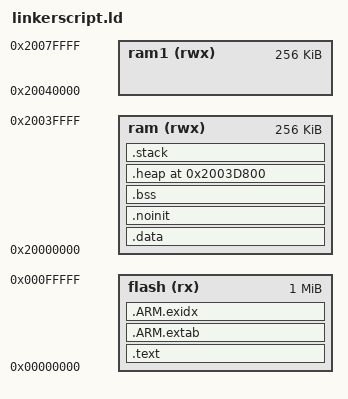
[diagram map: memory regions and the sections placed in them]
/* The MIT License (MIT)
 *
 * Copyright (c) 2021 Mathias Spiessens
 *
 * Permission is hereby granted, free of charge, to any person obtaining a copy
 * of this software, hardware and associated documentation files (the "Solution"), to deal
 * in the Solution without restriction, including without limitation the rights
 * to use, copy, modify, merge, publish, distribute, sublicense, and/or sell
 * copies of the Solution, and to permit persons to whom the Solution is
 * furnished to do so, subject to the following conditions:
 *
 * The above copyright notice and this permission notice shall be included in all
 * copies or substantial portions of the Solution.
 *
 * THE SOLUTION IS PROVIDED "AS IS", WITHOUT WARRANTY OF ANY KIND, EXPRESS OR
 * IMPLIED, INCLUDING BUT NOT LIMITED TO THE WARRANTIES OF MERCHANTABILITY,
 * FITNESS FOR A PARTICULAR PURPOSE AND NONINFRINGEMENT. IN NO EVENT SHALL THE
 * AUTHORS OR COPYRIGHT HOLDERS BE LIABLE FOR ANY CLAIM, DAMAGES OR OTHER
 * LIABILITY, WHETHER IN AN ACTION OF CONTRACT, TORT OR OTHERWISE, ARISING FROM,
 * OUT OF OR IN CONNECTION WITH THE SOLUTION OR THE USE OR OTHER DEALINGS IN THE
 * SOLUTION.
 */

OUTPUT_FORMAT ("elf32-littlearm", "elf32-bigarm", "elf32-littlearm")
SEARCH_DIR(.)
ENTRY(reset)

MEMORY
{
    flash (rx) : ORIGIN = 0x00000000, LENGTH = 1M 
    ram (rwx) : ORIGIN = 0x20000000, LENGTH = 256k
    ram1 (rwx) : ORIGIN = 0x20000000 + 256k, LENGTH = 256k
}

_heap_size = 8k;
_stack_size = 2k;

SECTIONS
{
    .text :
    {
        . = ALIGN(4);
        __Vectors = . ;
        KEEP(*(.vectors))

        . = ALIGN(4);
        *(.text*)

        KEEP(*(.init))
        KEEP(*(.fini))

        /* .ctors */
        *crtbegin.o(.ctors)
        *crtbegin?.o(.ctors)
        *(EXCLUDE_FILE(*crtend?.o *crtend.o) .ctors)
        *(SORT(.ctors.*))
        *(.ctors)

        /* .dtors */
        *crtbegin.o(.dtors)
        *crtbegin?.o(.dtors)
        *(EXCLUDE_FILE(*crtend?.o *crtend.o) .dtors)
        *(SORT(.dtors.*))
        *(.dtors)

        /* Read-only code (constants). */
        *(.rodata .rodata.* .constdata .constdata.* .conststring .conststring.*)

        KEEP(*(.eh_frame*))
    } > flash

    .ARM.extab :
    {
        *(.ARM.extab* .gnu.linkonce.armextab.*)
    } > flash

    __exidx_start = .;
    .ARM.exidx :
    {
        *(.ARM.exidx* .gnu.linkonce.armexidx.*)
    } > flash
    __exidx_end = .;
    
    _etext = .;

    .data : AT (_etext)
    {
        _data = .;
        KEEP(*(.ramVectors))

        *(vtable)
        *(.data*)

        . = ALIGN(4);
        /* preinit data */
        PROVIDE_HIDDEN (__preinit_array_start = .);
        KEEP(*(.preinit_array))
        PROVIDE_HIDDEN (__preinit_array_end = .);

        . = ALIGN(4);
        /* init data */
        PROVIDE_HIDDEN (__init_array_start = .);
        KEEP(*(SORT(.init_array.*)))
        KEEP(*(.init_array))
        PROVIDE_HIDDEN (__init_array_end = .);

        . = ALIGN(4);
        /* finit data */
        PROVIDE_HIDDEN (__fini_array_start = .);
        KEEP(*(SORT(.fini_array.*)))
        KEEP(*(.fini_array))
        PROVIDE_HIDDEN (__fini_array_end = .);

		_edata = .;
    } > ram

    .noinit (NOLOAD) : ALIGN(8)
    {
      KEEP(*(.noinit))
    } > ram

    .bss (NOLOAD):
    {
        . = ALIGN(4);
        _bss = .;
        __bss_start__ = .;
        *(.bss*)
        *(COMMON)
        . = ALIGN(4);
        _ebss = .;
        __bss_end__ = .;
    } > ram

    .heap (ORIGIN(ram) + LENGTH(ram) - _stack_size - _heap_size) (NOLOAD) :
    {
        . = ALIGN(8);
        _heap = .;
        . += _heap_size;
        . = ALIGN(8);
        _eheap = .;
    } > ram

    .stack (NOLOAD) :
    {
        . = ALIGN(8);
        . += _stack_size;
        . = ALIGN(8);
        _stack = . - 1;
    } > ram
}
